# KM1M7CF16 register map
Vendor: Nuvoton Technology Corporation Japan; Series: KM1M7CF; File version: 1.0.3
CPU: CM7 r1p2, little endian, MPU, FPU, double-precision FPU, I-cache, D-cache, ITCM, DTCM, 4 interrupt priority bits
Registers are 32-bit, read-write, no defined reset value unless marked. A register's access mark holds for its fields unless they carry their own. Offsets are from the block's base; [hi:lo] are bit positions; 'fields as' and 'values as' point back to an identical list.

## DAC — D/A Converter
Base 0x40027000
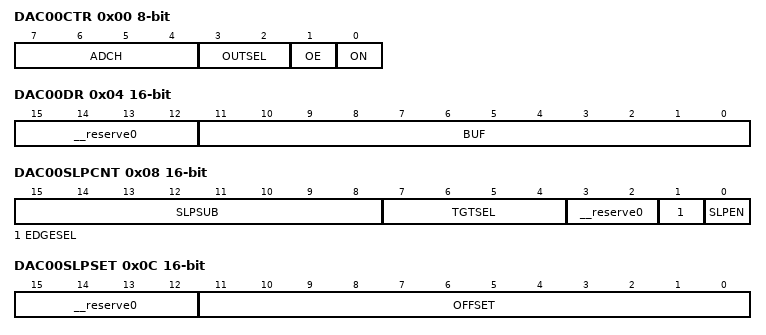
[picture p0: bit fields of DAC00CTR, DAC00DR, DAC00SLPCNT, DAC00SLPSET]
0x00 DAC00CTR 8-bit — DAC00 Control Register
  [7:4] ADCH — ADC conversion data buffer selection for DAC output
  [3:2] OUTSEL — DAOUT pin output data
  [1] OE — DAOUT pin output enable
  [0] ON — Operation control of D/A converter
0x04 DAC00DR 16-bit access per field — DAC00 Input Data Register
  [15:12] __reserve0 ro — "0" is always read out.
  [11:0] BUF rw — Set the input data that performs D/A conversion by DACn.
0x08 DAC00SLPCNT 16-bit access per field — DAC00 Slope Compensation Control Register
  [15:8] SLPSUB rw — Set slope compensation subtraction value.
  [7:4] TGTSEL rw — Slope compensation pin selection
  [3:2] __reserve0 ro — "0" is always read out.
  [1] EDGESEL rw — Slope compensation pin edge selection
  [0] SLPEN rw — D/An slope compensation enable
0x0C DAC00SLPSET 16-bit access per field — DAC00 Slope Compensation Setting Register
  [15:12] __reserve0 ro — "0" is always read out.
  [11:0] OFFSET rw — Set slope compensation subtraction start offset value.
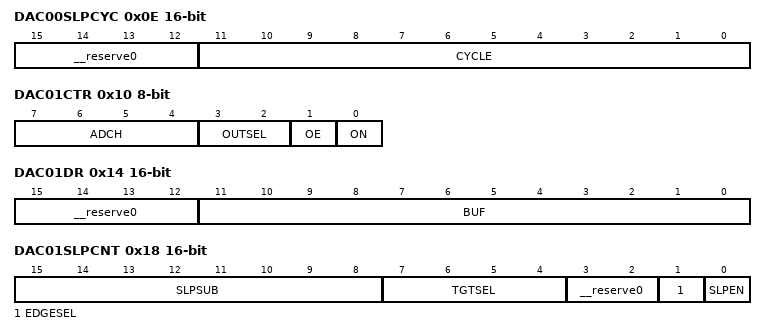
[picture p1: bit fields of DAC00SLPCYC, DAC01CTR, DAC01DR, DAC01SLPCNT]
0x0E DAC00SLPCYC 16-bit access per field — DAC00 Slope Compensation Cycle Register
  [15:12] __reserve0 ro — "0" is always read out.
  [11:0] CYCLE rw — Set slope compensation subtraction cycle.
0x10 DAC01CTR 8-bit — DAC01 Control Register
  fields as DAC00CTR
0x14 DAC01DR 16-bit access per field — DAC01 Input Data Register
  fields as DAC00DR
0x18 DAC01SLPCNT 16-bit access per field — DAC01 Slope Compensation Control Register
  fields as DAC00SLPCNT
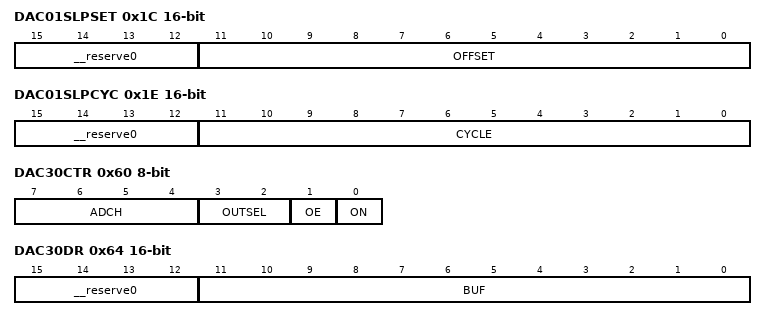
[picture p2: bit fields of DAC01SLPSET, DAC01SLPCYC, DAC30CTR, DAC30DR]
0x1C DAC01SLPSET 16-bit access per field — DAC01 Slope Compensation Setting Register
  fields as DAC00SLPSET
0x1E DAC01SLPCYC 16-bit access per field — DAC01 Slope Compensation Cycle Register
  fields as DAC00SLPCYC
0x60 DAC30CTR 8-bit — DAC30 Control Register
  fields as DAC00CTR
0x64 DAC30DR 16-bit access per field — DAC30 Input Data Register
  fields as DAC00DR
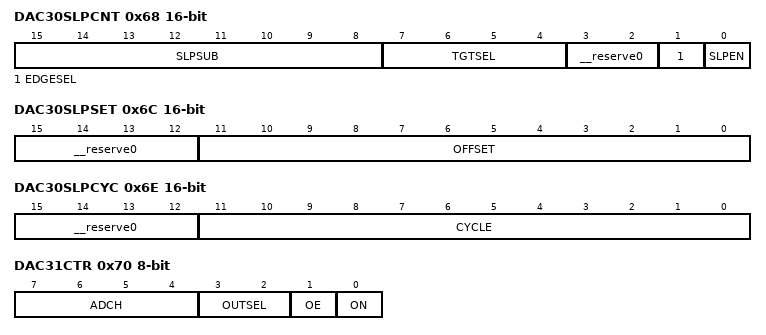
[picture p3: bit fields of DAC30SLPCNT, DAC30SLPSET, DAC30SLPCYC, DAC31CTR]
0x68 DAC30SLPCNT 16-bit access per field — DAC30 Slope Compensation Control Register
  fields as DAC00SLPCNT
0x6C DAC30SLPSET 16-bit access per field — DAC30 Slope Compensation Setting Register
  fields as DAC00SLPSET
0x6E DAC30SLPCYC 16-bit access per field — DAC30 Slope Compensation Cycle Register
  fields as DAC00SLPCYC
0x70 DAC31CTR 8-bit — DAC31 Control Register
  fields as DAC00CTR
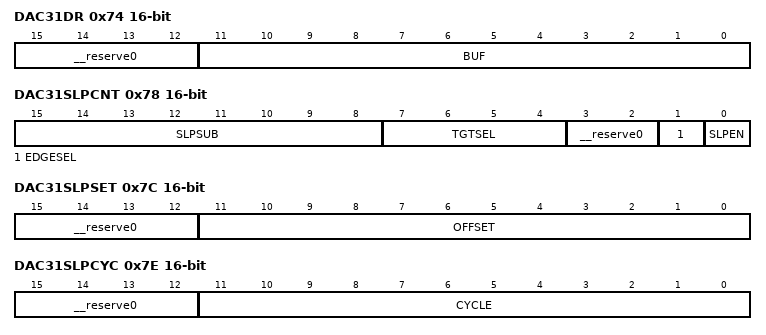
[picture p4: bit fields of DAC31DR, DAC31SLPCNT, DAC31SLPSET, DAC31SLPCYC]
0x74 DAC31DR 16-bit access per field — DAC31 Input Data Register
  fields as DAC00DR
0x78 DAC31SLPCNT 16-bit access per field — DAC31 Slope Compensation Control Register
  fields as DAC00SLPCNT
0x7C DAC31SLPSET 16-bit access per field — DAC31 Slope Compensation Setting Register
  fields as DAC00SLPSET
0x7E DAC31SLPCYC 16-bit access per field — DAC31 Slope Compensation Cycle Register
  fields as DAC00SLPCYC
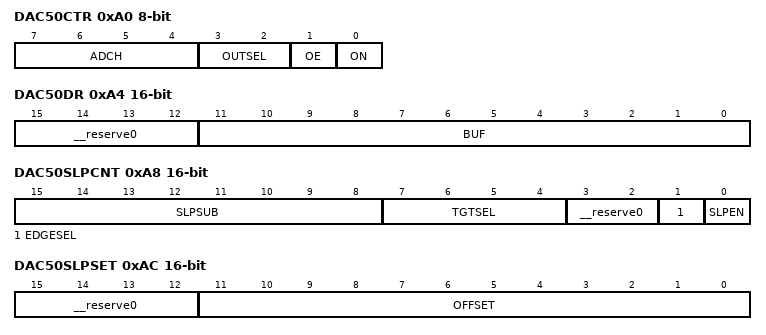
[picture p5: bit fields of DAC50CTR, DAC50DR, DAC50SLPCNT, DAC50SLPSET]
0xA0 DAC50CTR 8-bit — DAC50 Control Register
  fields as DAC00CTR
0xA4 DAC50DR 16-bit access per field — DAC50 Input Data Register
  fields as DAC00DR
0xA8 DAC50SLPCNT 16-bit access per field — DAC50 Slope Compensation Control Register
  fields as DAC00SLPCNT
0xAC DAC50SLPSET 16-bit access per field — DAC50 Slope Compensation Setting Register
  fields as DAC00SLPSET
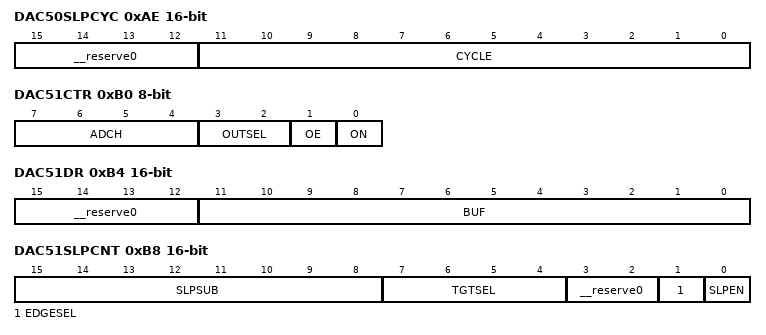
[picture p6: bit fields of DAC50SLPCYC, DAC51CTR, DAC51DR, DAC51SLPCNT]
0xAE DAC50SLPCYC 16-bit access per field — DAC50 Slope Compensation Cycle Register
  fields as DAC00SLPCYC
0xB0 DAC51CTR 8-bit — DAC51 Control Register
  fields as DAC00CTR
0xB4 DAC51DR 16-bit access per field — DAC51 Input Data Register
  fields as DAC00DR
0xB8 DAC51SLPCNT 16-bit access per field — DAC51 Slope Compensation Control Register
  fields as DAC00SLPCNT
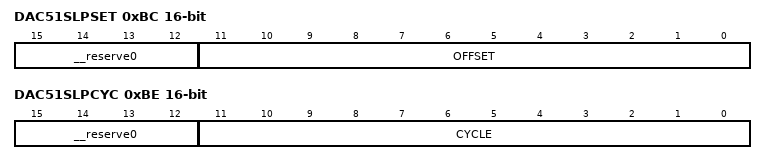
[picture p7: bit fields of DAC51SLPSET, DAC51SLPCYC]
0xBC DAC51SLPSET 16-bit access per field — DAC51 Slope Compensation Setting Register
  fields as DAC00SLPSET
0xBE DAC51SLPCYC 16-bit access per field — DAC51 Slope Compensation Cycle Register
  fields as DAC00SLPCYC
